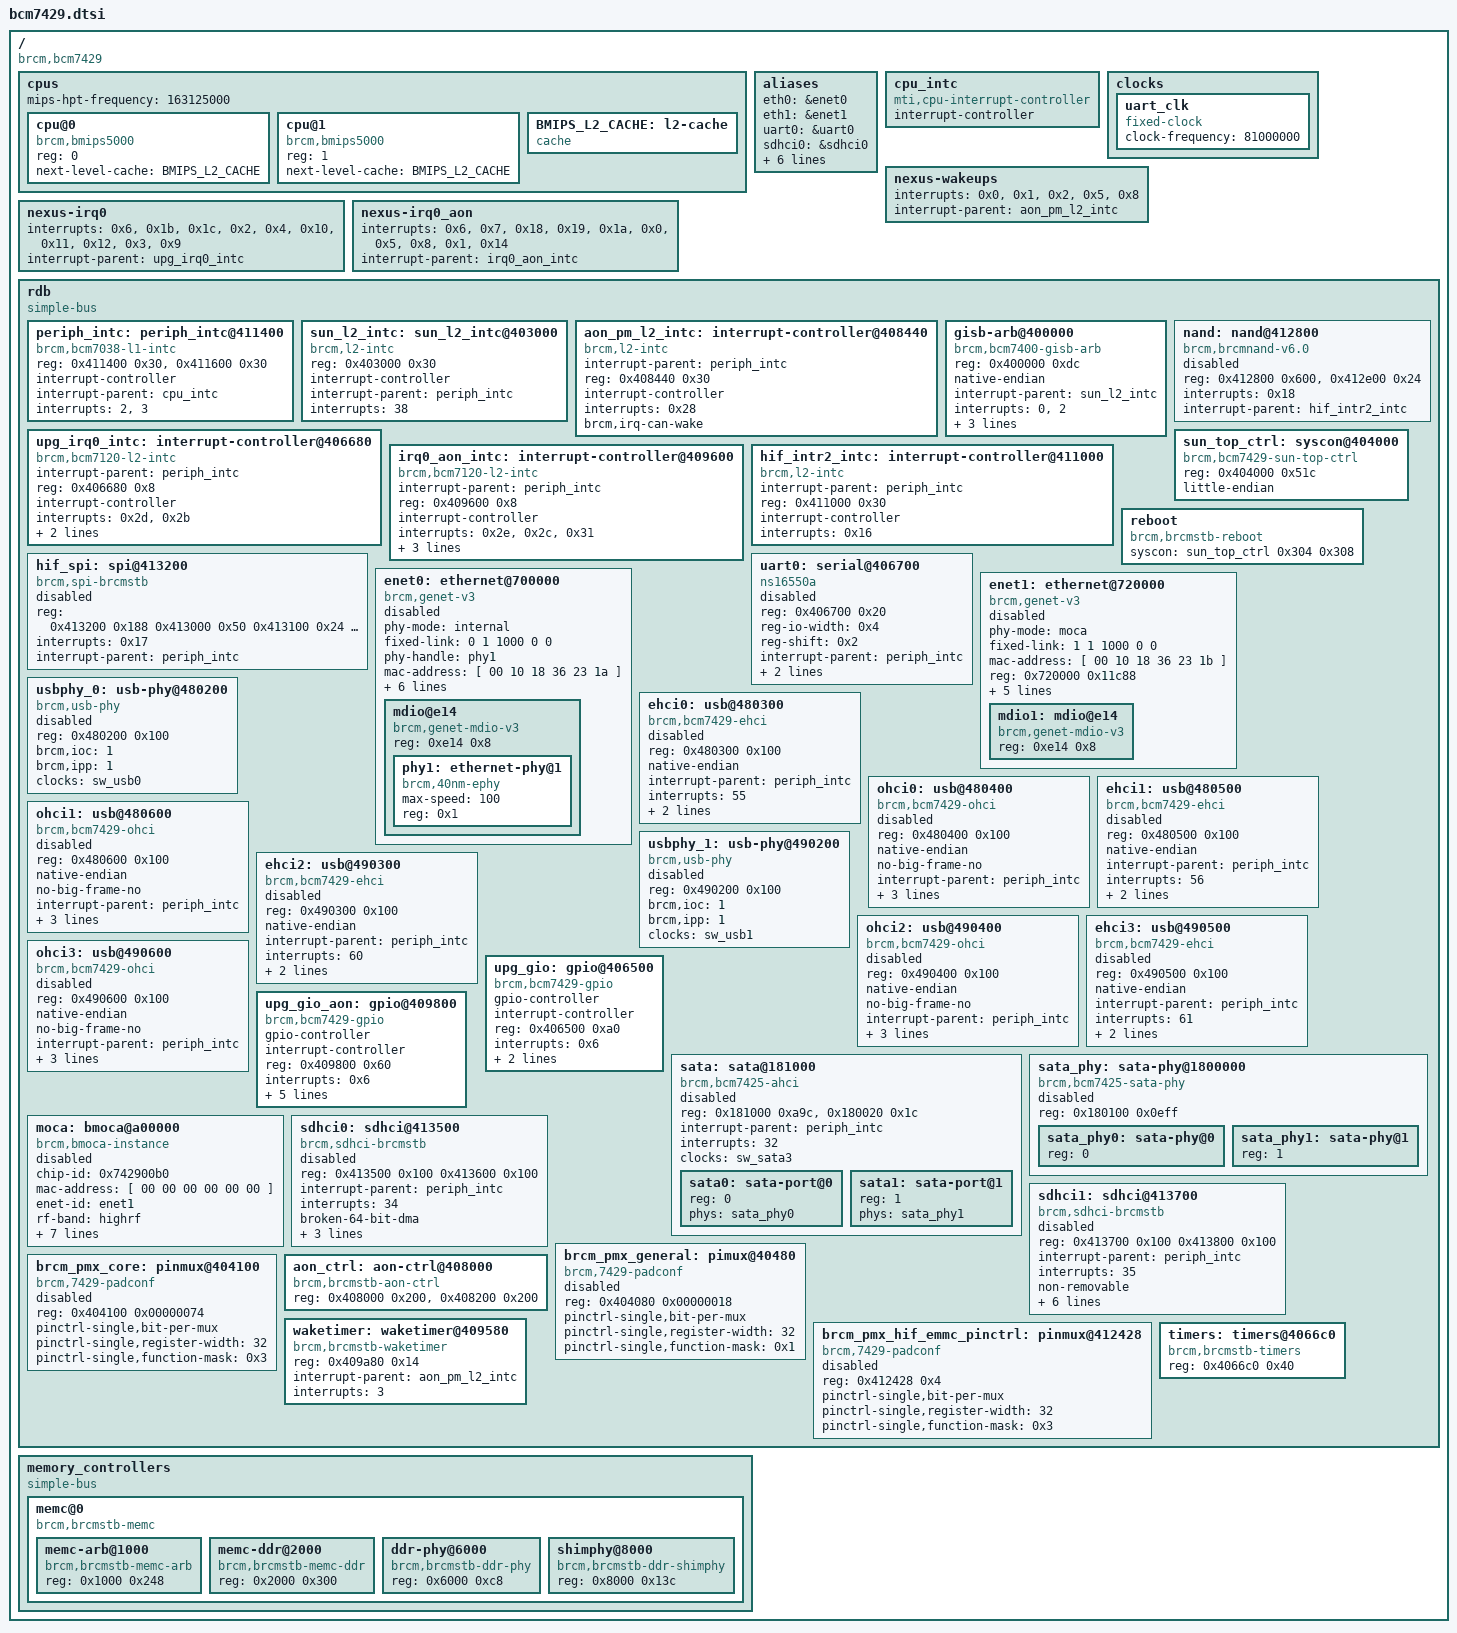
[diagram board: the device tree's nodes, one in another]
/include/ "clks-7429b0.dtsi"

/ {
	#address-cells = <1>;
	#size-cells = <1>;
	compatible = "brcm,bcm7429";

	cpus {
		#address-cells = <1>;
		#size-cells = <0>;

		mips-hpt-frequency = <163125000>;

		cpu@0 {
			compatible = "brcm,bmips5000";
			device_type = "cpu";
			reg = <0>;
			next-level-cache = <&BMIPS_L2_CACHE>;
		};

		cpu@1 {
			compatible = "brcm,bmips5000";
			device_type = "cpu";
			reg = <1>;
			next-level-cache = <&BMIPS_L2_CACHE>;
		};

		BMIPS_L2_CACHE: l2-cache {
			compatible = "cache";
		};
	};

	aliases {
		eth0 = &enet0;
		eth1 = &enet1;
		uart0 = &uart0;
		sdhci0 = &sdhci0;
		sdhci1 = &sdhci1;
		brcm_pmx_core = &brcm_pmx_core;
		moca = &moca;
		usbphy_0 = &usbphy_0;
		usbphy_1 = &usbphy_1;
		sata = &sata;
	};

	cpu_intc: cpu_intc {
		#address-cells = <0>;
		compatible = "mti,cpu-interrupt-controller";

		interrupt-controller;
		#interrupt-cells = <1>;
	};

	clocks {
		uart_clk: uart_clk {
			compatible = "fixed-clock";
			#clock-cells = <0>;
			clock-frequency = <81000000>;
		};
	};

	nexus-wakeups {
		interrupts = <0x0>,
			<0x1>,
			<0x2>,
			<0x5>,
			<0x8>;
		interrupt-parent = <&aon_pm_l2_intc>;
		interrupt-names = "cec",
			"irr",
			"kpd",
			"gpio",
			"xpt_pmu";
	};

	nexus-irq0 {
		interrupts = <0x6>,
			<0x1b>,
			<0x1c>,
			<0x2>,
			<0x4>,
			<0x10>,
			<0x11>,
			<0x12>,
			<0x3>,
			<0x9>;
		interrupt-parent = <&upg_irq0_intc>;
		interrupt-names = "gio",
			"iicd",
			"iice",
			"irb",
			"ua",
			"uarta",
			"uartb",
			"uartc",
			"ub",
			"uc";
	};

	nexus-irq0_aon {
		interrupts = <0x6>,
			<0x7>,
			<0x18>,
			<0x19>,
			<0x1a>,
			<0x0>,
			<0x5>,
			<0x8>,
			<0x1>,
			<0x14>;
		interrupt-parent = <&irq0_aon_intc>;
		interrupt-names = "gio",
			"icap",
			"iica",
			"iicb",
			"iicc",
			"kbd1",
			"kbd2",
			"kbd3",
			"ldk",
			"spi";
	};

	rdb {
		#address-cells = <1>;
		#size-cells = <1>;

		compatible = "simple-bus";
		ranges = <0 0x10000000 0x01000000>;

		periph_intc: periph_intc@411400 {
			compatible = "brcm,bcm7038-l1-intc";
			reg = <0x411400 0x30>, <0x411600 0x30>;

			interrupt-controller;
			#interrupt-cells = <1>;

			interrupt-parent = <&cpu_intc>;
			interrupts = <2>, <3>;
		};

		sun_l2_intc: sun_l2_intc@403000 {
			compatible = "brcm,l2-intc";
			reg = <0x403000 0x30>;
			interrupt-controller;
			#interrupt-cells = <1>;
			interrupt-parent = <&periph_intc>;
			interrupts = <38>;
		};

		aon_pm_l2_intc: interrupt-controller@408440 {
			#interrupt-cells = <1>;
			compatible = "brcm,l2-intc";
			interrupt-parent = <&periph_intc>;
			reg = <0x408440 0x30>;
			interrupt-controller;
			interrupts = <0x28>;
			interrupt-names = "sys_pm";
			brcm,irq-can-wake;
		};

		gisb-arb@400000 {
			compatible = "brcm,bcm7400-gisb-arb";
			reg = <0x400000 0xdc>;
			native-endian;
			interrupt-parent = <&sun_l2_intc>;
			interrupts = <0>, <2>;
			brcm,gisb-arb-master-mask = <0x673>;
			brcm,gisb-arb-master-names = "ssp_0", "cpu_0",
						     "bsp_0", "rdc_0",
						     "raaga_0", "jtag_0",
						     "svd_0";
		};

		upg_irq0_intc: interrupt-controller@406680 {
			#interrupt-cells = <1>;
			compatible = "brcm,bcm7120-l2-intc";
			interrupt-parent = <&periph_intc>;
			reg = <0x406680 0x8>;
			interrupt-controller;
			interrupts = <0x2d>,
				<0x2b>;
			interrupt-names = "upg_main",
				"upg_bsc";
			brcm,int-map-mask = <0x25c>,
				<0x18000000>;
			brcm,int-fwd-mask = <0x70000>;
		};

		irq0_aon_intc: interrupt-controller@409600 {
			#interrupt-cells = <1>;
			compatible = "brcm,bcm7120-l2-intc";
			interrupt-parent = <&periph_intc>;
			reg = <0x409600 0x8>;
			interrupt-controller;
			interrupts = <0x2e>,
				<0x2c>,
				<0x31>;
			interrupt-names = "upg_main_aon",
				"upg_bsc_aon",
				"upg_spi";
			brcm,int-map-mask = <0x1e3>,
				<0x7000000>,
				<0x100000>;
			brcm,int-fwd-mask = <0x0>;
			brcm,irq-can-wake;
		};

		hif_intr2_intc: interrupt-controller@411000 {
			#interrupt-cells = <1>;
			compatible = "brcm,l2-intc";
			interrupt-parent = <&periph_intc>;
			reg = <0x411000 0x30>;
			interrupt-controller;
			interrupts = <0x16>;
			interrupt-names = "hif";
		};

		hif_spi: spi@413200 {
			#address-cells = <1>;
			#size-cells = <0>;
			compatible = "brcm,spi-brcmstb",
				"brcm,spi-bcm7429-qspi",
				"brcm,spi-bcm-qspi";
			status = "disabled";
			reg = <0x413200 0x188 0x413000 0x50
				0x413100 0x24 0x411d00 0x30
				0x410920 0x4>;
			reg-names = "hif_mspi",
				"bspi",
				"bspi_raf",
				"hif_spi_intr2",
				"cs_reg";
			interrupts = <0x17>;
			interrupt-parent = <&periph_intc>;
			interrupt-names = "hif_spi";
		};

		nand: nand@412800 {
			#address-cells = <1>;
			#size-cells = <0>;
			compatible = "brcm,brcmnand-v6.0",
				"brcm,brcmnand";
			reg-names = "nand", "flash-edu";
			status = "disabled";
			reg = <0x412800 0x600>, <0x412e00 0x24>;
			interrupts = <0x18>;
			interrupt-parent = <&hif_intr2_intc>;
			interrupt-names = "nand_ctlrdy";
		};

		sun_top_ctrl: syscon@404000 {
			compatible = "brcm,bcm7429-sun-top-ctrl", "syscon";
			reg = <0x404000 0x51c>;
			little-endian;
		};

		reboot {
			compatible = "brcm,brcmstb-reboot";
			syscon = <&sun_top_ctrl 0x304 0x308>;
		};

		uart0: serial@406700 {
			compatible = "ns16550a";
			reg = <0x406700 0x20>;
			reg-io-width = <0x4>;
			reg-shift = <0x2>;
			interrupt-parent = <&periph_intc>;
			interrupts = <51>;
			clocks = <&uart_clk>;
			status = "disabled";
		};

		enet0: ethernet@700000 {
			phy-mode = "internal";
			fixed-link = <0 1 1000 0 0>;
			phy-handle = <&phy1>;
			mac-address = [ 00 10 18 36 23 1a ];
			compatible = "brcm,genet-v3";
			#address-cells = <0x1>;
			#size-cells = <0x1>;
			reg = <0x700000 0x11c88>;
			interrupts = <15>, <16>;
			interrupt-parent = <&periph_intc>;
			interrupts-extended = <&periph_intc 15>,
					<&periph_intc 16>,
					<&aon_pm_l2_intc 7>;
			status = "disabled";
			clocks = <&sw_genet0>, <&sw_genetwol0>, <&sw_geneteee0>;
			clock-names = "sw_genet", "sw_genetwol", "sw_geneteee";

			mdio@e14 {
				compatible = "brcm,genet-mdio-v3";
				#address-cells = <0x1>;
				#size-cells = <0x0>;
				reg = <0xe14 0x8>;
				status = "okay";

				phy1: ethernet-phy@1 {
					max-speed = <100>;
					reg = <0x1>;
					compatible = "brcm,40nm-ephy",
						"ethernet-phy-ieee802.3-c22";
				};
			};
		};

		enet1: ethernet@720000 {
			phy-mode = "moca";
			fixed-link = <1 1 1000 0 0>;
			mac-address = [ 00 10 18 36 23 1b ];
			compatible = "brcm,genet-v3";
			#address-cells = <0x1>;
			#size-cells = <0x1>;
			reg = <0x720000 0x11c88>;
			interrupts = <17>, <18>;
			interrupt-parent = <&periph_intc>;
			interrupts-extended = <&periph_intc 17>,
					<&periph_intc 18>,
					<&aon_pm_l2_intc 6>;
			status = "disabled";
			clocks = <&sw_genet1>, <&sw_genetwol1>, <&sw_geneteee1>;
			clock-names = "sw_genet", "sw_genetwol", "sw_geneteee";

			mdio1: mdio@e14 {
				compatible = "brcm,genet-mdio-v3";
				#address-cells = <0x1>;
				#size-cells = <0x0>;
				reg = <0xe14 0x8>;

			};
		};


		usbphy_0: usb-phy@480200 {
			reg = <0x480200 0x100>;
			#address-cells = <1>;
			#size-cells = <1>;
			compatible = "brcm,usb-phy";
			status = "disabled";
			brcm,ioc = <1>;
			brcm,ipp = <1>;
			#phy-cells = <1>;
			ranges;
			clocks = <&sw_usb0>;
			clock-names = "sw_usb";
		};

		ehci0: usb@480300 {
			compatible = "brcm,bcm7429-ehci",
				   "brcm,ehci-brcm-v2" , "generic-ehci";
			reg = <0x480300 0x100>;
			native-endian;
			interrupt-parent = <&periph_intc>;
			interrupts = <55>;
			status = "disabled";
			clocks = <&sw_usb0>;
			clock-names = "sw_usb";
			phys = <&usbphy_0 0x0>;
			phy-names = "usbphy";
		};

		ohci0: usb@480400 {
			compatible = "brcm,bcm7429-ohci",
				   "brcm,ohci-brcm-v2", "generic-ohci";
			reg = <0x480400 0x100>;
			native-endian;
			no-big-frame-no;
			interrupt-parent = <&periph_intc>;
			interrupts = <57>;
			status = "disabled";
			clocks = <&sw_usb0>;
			clock-names = "sw_usb";
			phys = <&usbphy_0 0x0>;
			phy-names = "usbphy";
		};

		ehci1: usb@480500 {
			compatible = "brcm,bcm7429-ehci",
				   "brcm,ehci-brcm-v2", "generic-ehci";
			reg = <0x480500 0x100>;
			native-endian;
			interrupt-parent = <&periph_intc>;
			interrupts = <56>;
			status = "disabled";
			clocks = <&sw_usb0>;
			clock-names = "sw_usb";
			phys = <&usbphy_0 0x0>;
			phy-names = "usbphy";
		};

		ohci1: usb@480600 {
			compatible = "brcm,bcm7429-ohci",
				   "brcm,ohci-brcm-v2", "generic-ohci";
			reg = <0x480600 0x100>;
			native-endian;
			no-big-frame-no;
			interrupt-parent = <&periph_intc>;
			interrupts = <58>;
			status = "disabled";
			clocks = <&sw_usb0>;
			clock-names = "sw_usb";
			phys = <&usbphy_0 0x0>;
			phy-names = "usbphy";
		};

		usbphy_1: usb-phy@490200 {
			reg = <0x490200 0x100>;
			#address-cells = <1>;
			#size-cells = <1>;
			compatible = "brcm,usb-phy";
			status = "disabled";
			brcm,ioc = <1>;
			brcm,ipp = <1>;
			#phy-cells = <1>;
			ranges;
			clocks = <&sw_usb1>;
			clock-names = "sw_usb";
		};

		ehci2: usb@490300 {
			compatible = "brcm,bcm7429-ehci",
				   "brcm,ehci-brcm-v2", "generic-ehci";
			reg = <0x490300 0x100>;
			native-endian;
			interrupt-parent = <&periph_intc>;
			interrupts = <60>;
			status = "disabled";
			clocks = <&sw_usb1>;
			clock-names = "sw_usb";
			phys = <&usbphy_1 0x0>;
			phy-names = "usbphy";
		};

		ohci2: usb@490400 {
			compatible = "brcm,bcm7429-ohci",
				   "brcm,ohci-brcm-v2", "generic-ohci";
			reg = <0x490400 0x100>;
			native-endian;
			no-big-frame-no;
			interrupt-parent = <&periph_intc>;
			interrupts = <62>;
			status = "disabled";
			clocks = <&sw_usb1>;
			clock-names = "sw_usb";
			phys = <&usbphy_1 0x0>;
			phy-names = "usbphy";
		};

		ehci3: usb@490500 {
			compatible = "brcm,bcm7429-ehci",
				   "brcm,ehci-brcm-v2", "generic-ehci";
			reg = <0x490500 0x100>;
			native-endian;
			interrupt-parent = <&periph_intc>;
			interrupts = <61>;
			status = "disabled";
			clocks = <&sw_usb1>;
			clock-names = "sw_usb";
			phys = <&usbphy_1 0x0>;
			phy-names = "usbphy";
		};

		ohci3: usb@490600 {
			compatible = "brcm,bcm7429-ohci",
				   "brcm,ohci-brcm-v2", "generic-ohci";
			reg = <0x490600 0x100>;
			native-endian;
			no-big-frame-no;
			interrupt-parent = <&periph_intc>;
			interrupts = <63>;
			status = "disabled";
			clocks = <&sw_usb1>;
			clock-names = "sw_usb";
			phys = <&usbphy_1 0x0>;
			phy-names = "usbphy";
		};

		upg_gio: gpio@406500 {
			#gpio-cells = <2>;
			#interrupt-cells = <2>;
			compatible = "brcm,bcm7429-gpio",
				"brcm,brcmstb-gpio";
			gpio-controller;
			interrupt-controller;
			reg = <0x406500 0xa0>;
			interrupts = <0x6>;
			interrupt-parent = <&upg_irq0_intc>;
			interrupt-names = "upg_gio";
			brcm,gpio-bank-widths = <32 32 32 32
				26>;
		};

		upg_gio_aon: gpio@409800 {
			#gpio-cells = <2>;
			#interrupt-cells = <2>;
			compatible = "brcm,bcm7429-gpio",
				"brcm,brcmstb-gpio";
			gpio-controller;
			interrupt-controller;
			reg = <0x409800 0x60>;
			interrupts = <0x6>;
			interrupt-parent = <&irq0_aon_intc>;
			interrupts-extended = <&irq0_aon_intc 0x6>,
				<&aon_pm_l2_intc 0x5>;
			interrupt-names = "upg_gio_aon",
				"upg_gio_aon_wakeup";
			wakeup-source;
			brcm,gpio-bank-widths = <21 0 6>;
		};

		sata: sata@181000 {
			compatible = "brcm,bcm7425-ahci", "brcm,sata3-ahci";
			reg-names = "ahci", "top-ctrl";
			reg = <0x181000 0xa9c>, <0x180020 0x1c>;
			interrupt-parent = <&periph_intc>;
			interrupts = <32>;
			#address-cells = <1>;
			#size-cells = <0>;
			status = "disabled";
			clocks = <&sw_sata3>;
			clock-names = "sw_sata3";

			sata0: sata-port@0 {
				reg = <0>;
				phys = <&sata_phy0>;
			};

			sata1: sata-port@1 {
				reg = <1>;
				phys = <&sata_phy1>;
			};
		};

		sata_phy: sata-phy@1800000 {
			compatible = "brcm,bcm7425-sata-phy", "brcm,phy-sata3";
			reg = <0x180100 0x0eff>;
			reg-names = "phy";
			#address-cells = <1>;
			#size-cells = <0>;
			status = "disabled";

			sata_phy0: sata-phy@0 {
				reg = <0>;
				#phy-cells = <0>;
			};

			sata_phy1: sata-phy@1 {
				reg = <1>;
				#phy-cells = <0>;
			};
		};

		moca: bmoca@a00000 {
			chip-id = <0x742900b0>;
			mac-address = [ 00 00 00 00 00 00 ];
			enet-id = <&enet1>;
			rf-band = "highrf";
			compatible = "brcm,bmoca-instance";
			hw-rev = <0x2002>;
			reg = <0xa00000 0x1ffd94>;
			interrupts = <27>;
			interrupt-parent = <&periph_intc>;
			interrupt-names = "moca";
			i2c-base = <0x10406200>;
			i2c-addr = <0x70>;
			status = "disabled";
			clocks = <&sw_moca>, <&sw_mocawol>;
			clock-names = "sw_moca", "sw_mocawol";

		};
		sdhci0: sdhci@413500 {
			compatible = "brcm,sdhci-brcmstb";
			reg = <0x413500 0x100 0x413600 0x100>;
			reg-names = "host", "cfg";
			interrupt-parent = <&periph_intc>;
			interrupts = <34>;
			broken-64-bit-dma;
			sdhci,auto-cmd12;
			no-1-8-v;
			status = "disabled";
			clocks = <&sw_sdio>;
			clock-names = "sw_sdio";
		};
		sdhci1: sdhci@413700 {
			compatible = "brcm,sdhci-brcmstb";
			reg = <0x413700 0x100 0x413800 0x100>;
			reg-names = "host", "cfg";
			interrupt-parent = <&periph_intc>;
			interrupts = <35>;
			non-removable;
			bus-width = <0x8>;
			broken-64-bit-dma;
			broken-timeout-value;
			sdhci,auto-cmd12;
			no-1-8-v;
			status = "disabled";
			clocks = <&sw_sdio>;
			clock-names = "sw_sdio";
		};
		brcm_pmx_general: pimux@40480 {
			compatible = "brcm,7429-padconf", "pinctrl-single";
			reg = <0x404080 0x00000018>;
			#address-cells = <1>;
			#size-cells = <0>;
			pinctrl-single,bit-per-mux;
			pinctrl-single,register-width = <32>;
			pinctrl-single,function-mask = <0x1>;
			status = "disabled";
		};
		brcm_pmx_core: pinmux@404100 {
			compatible = "brcm,7429-padconf", "pinctrl-single";
			reg = <0x404100 0x00000074>;
			#address-cells = <1>;
			#size-cells = <0>;
			pinctrl-single,bit-per-mux;
			pinctrl-single,register-width = <32>;
			pinctrl-single,function-mask = <0x3>;
			status = "disabled";
		};
		brcm_pmx_hif_emmc_pinctrl: pinmux@412428 {
			compatible = "brcm,7429-padconf", "pinctrl-single";
			reg = <0x412428 0x4>;
			#address-cells = <1>;
			#size-cells = <0>;
			pinctrl-single,bit-per-mux;
			pinctrl-single,register-width = <32>;
			pinctrl-single,function-mask = <0x3>;
			status = "disabled";
		};
		aon_ctrl: aon-ctrl@408000 {
			compatible = "brcm,brcmstb-aon-ctrl";
			reg = <0x408000 0x200>, <0x408200 0x200>;
			reg-names = "aon-ctrl", "aon-sram";
		};
		waketimer: waketimer@409580 {
			compatible = "brcm,brcmstb-waketimer";
			reg = <0x409a80 0x14>;
			interrupt-parent = <&aon_pm_l2_intc>;
			interrupts = <3>;
			interrupt-names = "timer";
		};
		timers: timers@4066c0 {
			compatible = "brcm,brcmstb-timers";
			reg = <0x4066c0 0x40>;
		};
	};

	memory_controllers {
		compatible = "simple-bus";
		ranges = <0x0 0x103b0000 0xa000>;
		#address-cells = <1>;
		#size-cells = <1>;

		memc@0 {
			compatible = "brcm,brcmstb-memc", "simple-bus";
			ranges = <0x0 0x0 0xa000>;
			#address-cells = <1>;
			#size-cells = <1>;

			memc-arb@1000 {
				compatible = "brcm,brcmstb-memc-arb";
				reg = <0x1000 0x248>;
			};

			memc-ddr@2000 {
				compatible = "brcm,brcmstb-memc-ddr";
				reg = <0x2000 0x300>;
			};

			ddr-phy@6000 {
				compatible = "brcm,brcmstb-ddr-phy";
				reg = <0x6000 0xc8>;
			};

			shimphy@8000 {
				compatible = "brcm,brcmstb-ddr-shimphy";
				reg = <0x8000 0x13c>;
			};
		};
	};
};
